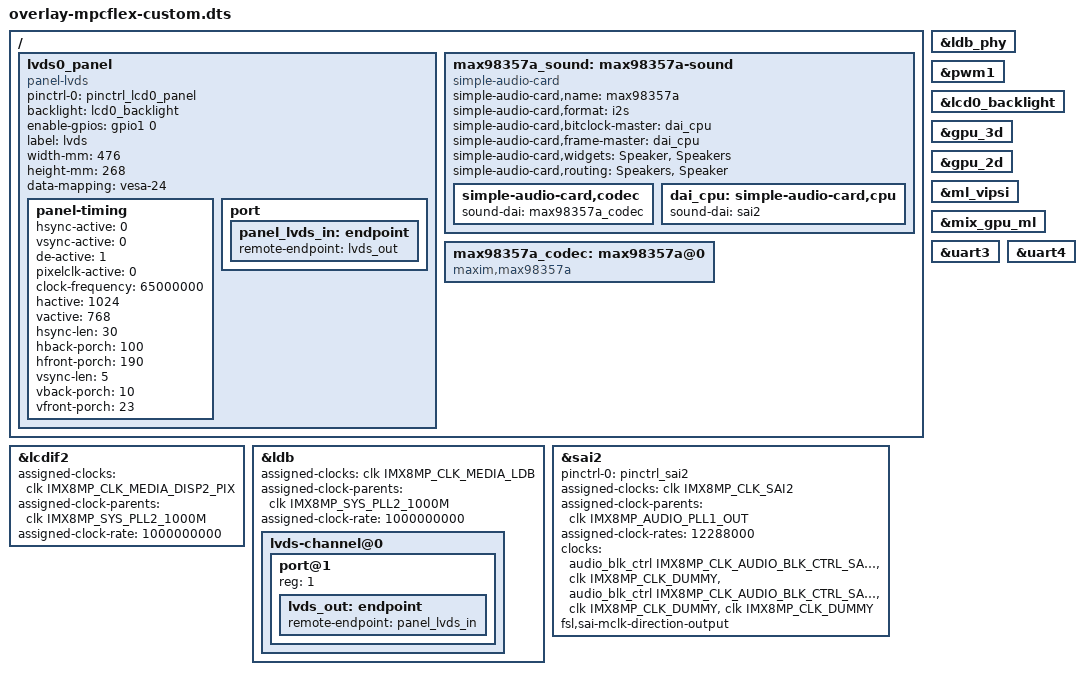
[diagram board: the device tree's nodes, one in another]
/*
 * Copyright (C) 2023 Berg Propulsion
 * Copyright (C) 2022 Avnet Embedded GmbH
 *
 * This program is free software; you can redistribute it and/or
 * modify it under the terms of the GNU General Public License as
 * published by the Free Software Foundation version 2.
 *
 * This program is distributed "as is" WITHOUT ANY WARRANTY of any
 * kind, whether express or implied; without even the implied warranty
 * of MERCHANTABILITY or FITNESS FOR A PARTICULAR PURPOSE.  See the
 * GNU General Public License for more details.
 */

/dts-v1/;
/plugin/;

#include <dt-bindings/gpio/gpio.h>
#include <dt-bindings/clock/imx8mp-clock.h>

/ {
	fragment@4000 {
		target-path = "/";
		__overlay__ {
			lvds0_panel {
				pinctrl-names = "default";
				pinctrl-0 = <&pinctrl_lcd0_panel>;
				compatible = "panel-lvds";
				backlight = <&lcd0_backlight>;
				enable-gpios =  <&gpio1 0 GPIO_ACTIVE_HIGH>;

				label = "lvds";
				width-mm = <476>;
				height-mm = <268>;
				data-mapping = "vesa-24";

				panel-timing {
					// On the Kontron system we did not set these 4 parameters
					hsync-active = <0>;
					vsync-active = <0>;
					de-active = <1>;
					pixelclk-active = <0>;

					// These are the parameters we have determined for the display used in the mpcflex product
					clock-frequency = <65000000>;
					hactive = <1024>;
					vactive = <768>;
					hsync-len = <30>;
					hback-porch = <100>;
					hfront-porch = <190>;
					vsync-len = <5>;
					vback-porch = <10>;
					vfront-porch = <23>;
				};

				port {
					panel_lvds_in: endpoint {
						remote-endpoint = <&lvds_out>;
					};
				};
			};
		};
	};

	// Can we remove these clock modifications and still have working display?
	fragment@4001 {
		target = <&lcdif2>;
		__overlay__ {
			assigned-clocks = <&clk IMX8MP_CLK_MEDIA_DISP2_PIX>;
			assigned-clock-parents = <&clk IMX8MP_SYS_PLL2_1000M>;
			assigned-clock-rate = <1000000000>;
			status = "okay";
		};
	};

	// Can we remove these clock modifications and still have working display?
	fragment@4002 {
		target = <&ldb>;
		__overlay__ {
			assigned-clocks = <&clk IMX8MP_CLK_MEDIA_LDB>;
			assigned-clock-parents = <&clk IMX8MP_SYS_PLL2_1000M>;
			assigned-clock-rate = <1000000000>;
			status = "okay";

			// This is most likely needed since it connects together display node above with the lvds channel
			lvds-channel@0 {
				#address-cells = <1>;
				#size-cells = <0>;
				status = "okay";

				port@1 {
					reg = <1>;

					lvds_out: endpoint {
						remote-endpoint = <&panel_lvds_in>;
					};
				};
			};
		};
	};

	fragment@4003 {
		target = <&ldb_phy>;
		__overlay__ {
			status = "okay";
		};
	};

	fragment@4004 {
		target = <&pwm1>;
		__overlay__ {
			status = "okay";
		};
	};

	fragment@4005 {
		target = <&lcd0_backlight>;
		__overlay__ {
			status = "okay";
		};
	};

	fragment@4006 {
		target = <&gpu_3d>;
		__overlay__ {
			status = "okay";
		};
	};

	fragment@4007 {
		target = <&gpu_2d>;
		__overlay__ {
			status = "okay";
		};
	};

	fragment@4008 {
		target = <&ml_vipsi>;
		__overlay__ {
			status = "okay";
		};
	};

	fragment@4009 {
		target = <&mix_gpu_ml>;
		__overlay__ {
			status = "okay";
		};
	};

	fragment@4010 {
		target = <&uart3>;
		__overlay__ {
			status = "okay";
		};
	};

	fragment@4011 {
		target = <&uart4>;
		__overlay__ {
			status = "okay";
		};
	};

	fragment@4012 {
		target-path = "/";
		__overlay__ {
			max98357a_sound: max98357a-sound {
				compatible = "simple-audio-card";
				simple-audio-card,name = "max98357a";
				simple-audio-card,format = "i2s";
				simple-audio-card,bitclock-master = <&dai_cpu>;
				simple-audio-card,frame-master = <&dai_cpu>;
				simple-audio-card,widgets = "Speaker", "Speakers";
				simple-audio-card,routing = "Speakers", "Speaker";
				status = "okay";

				simple-audio-card,codec {
				    sound-dai = <&max98357a_codec>;
				};
				dai_cpu: simple-audio-card,cpu {
				    sound-dai = <&sai2>;
				};
			};
		};
	};

	fragment@4013 {
		target-path = "/";
		__overlay__ {
			max98357a_codec: max98357a@0 {
			    compatible = "maxim,max98357a";
			    #sound-dai-cells = <0>;
			};
		};
	};

	fragment@4014 {
		target = <&sai2>;
		__overlay__ {
			pinctrl-names = "default";
			pinctrl-0 = <&pinctrl_sai2>;
			assigned-clocks = <&clk IMX8MP_CLK_SAI2>;
			assigned-clock-parents = <&clk IMX8MP_AUDIO_PLL1_OUT>;
			assigned-clock-rates = <12288000>;
			clocks = <&audio_blk_ctrl IMX8MP_CLK_AUDIO_BLK_CTRL_SAI2_IPG>,
				<&clk IMX8MP_CLK_DUMMY>,
				<&audio_blk_ctrl IMX8MP_CLK_AUDIO_BLK_CTRL_SAI2_MCLK1>,
				<&clk IMX8MP_CLK_DUMMY>,
				<&clk IMX8MP_CLK_DUMMY>;
			clock-names = "bus", "mclk0", "mclk1", "mclk2", "mclk3";
			fsl,sai-mclk-direction-output;
			status = "okay";
		};
	};
};
